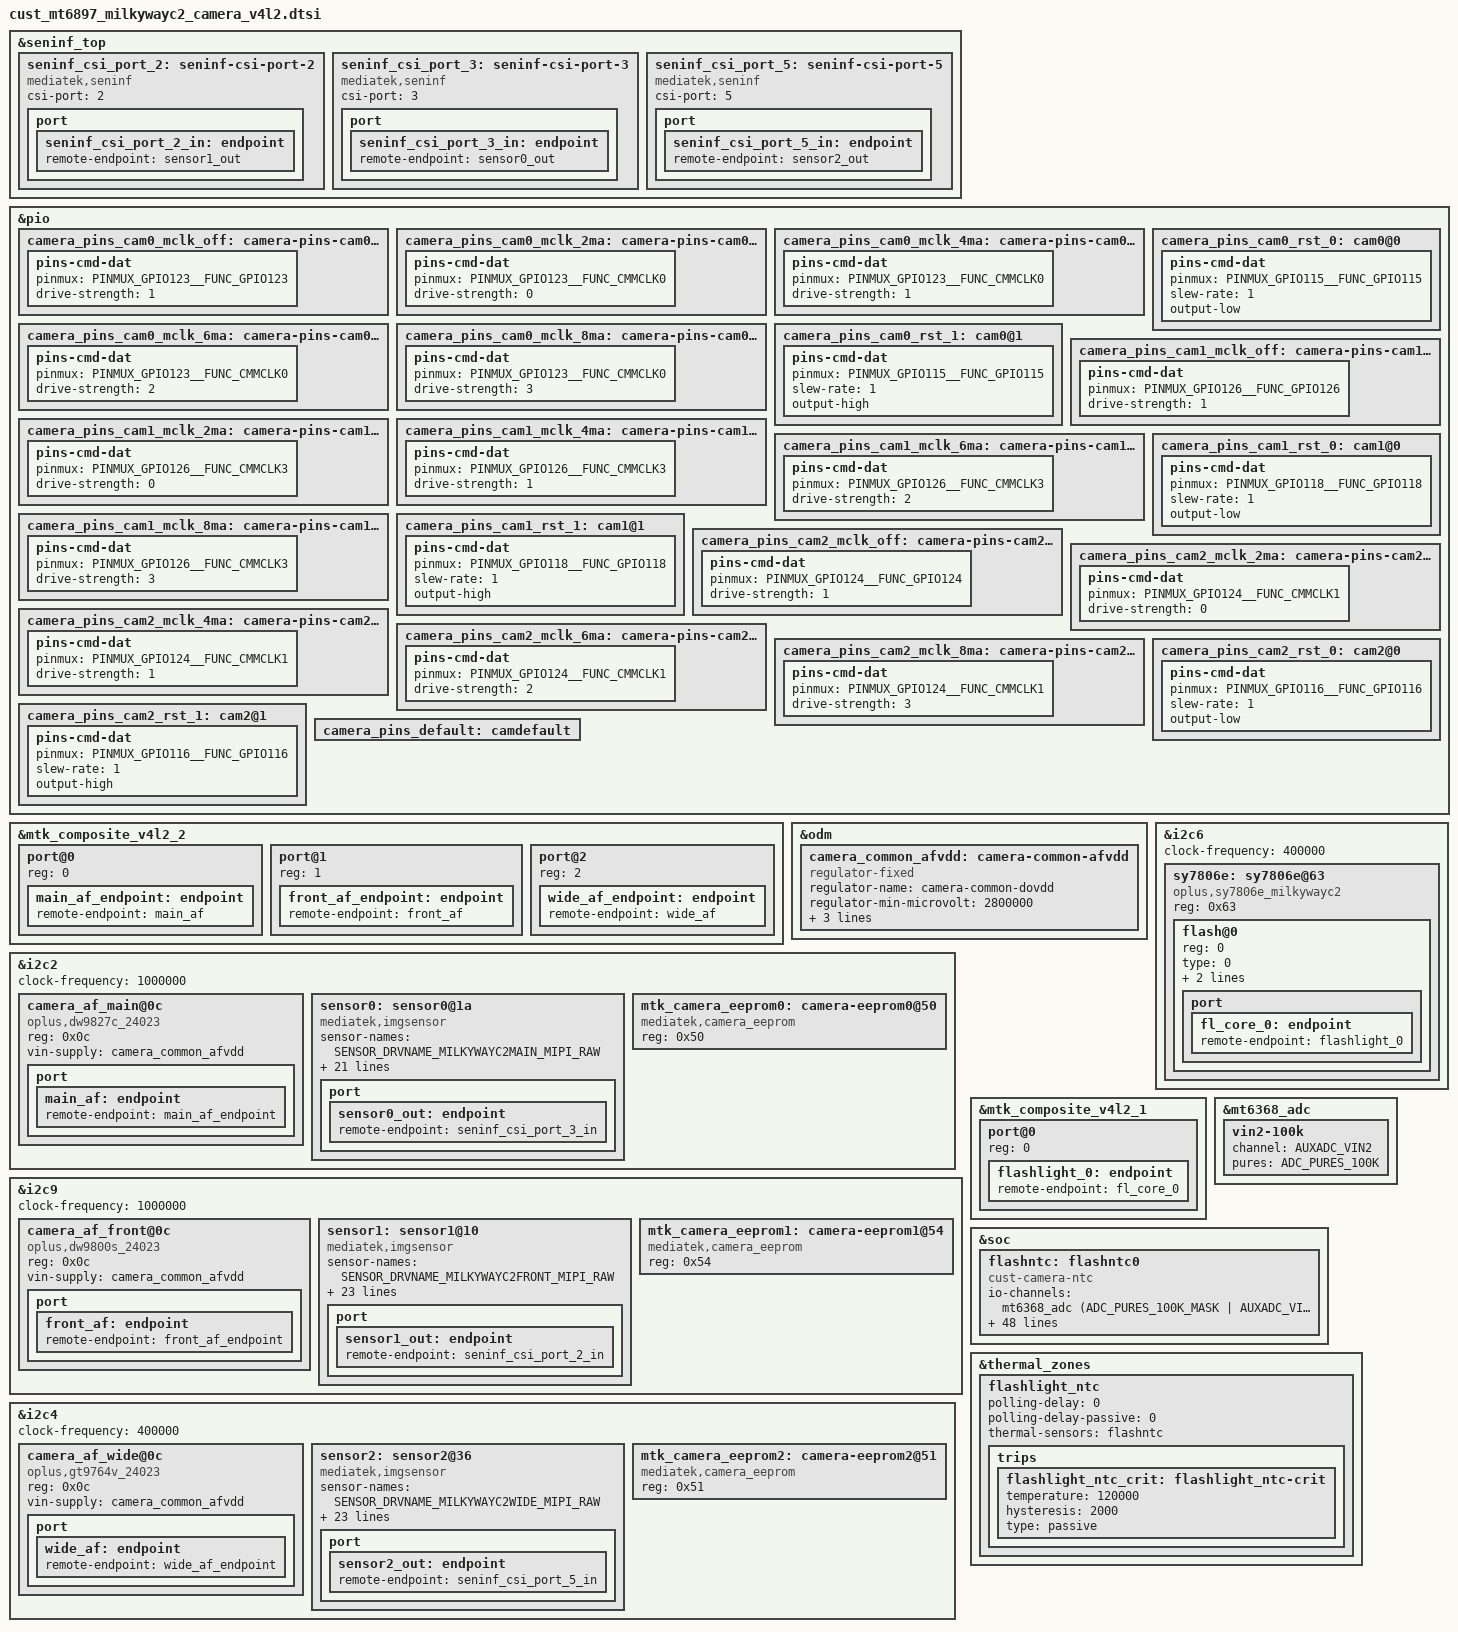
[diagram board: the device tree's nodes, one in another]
// SPDX-License-Identifier: GPL-2.0
/* Copyright (c) 2020 MediaTek Inc. */
#include <dt-bindings/clock/mt6897-clk.h>
#include "mediatek/milkywayc2_regulator_aw37004dnr.dtsi"
#include "../../../../../../vendor/oplus/kernel/camera/imgsensor/inc/oplus_kd_imgsensor.h"

&seninf_top {
		seninf_csi_port_2: seninf-csi-port-2 {
			compatible = "mediatek,seninf";
			csi-port = "2";

			port {
				seninf_csi_port_2_in: endpoint {
					remote-endpoint = <&sensor1_out>;
				};
			};
		};

		seninf_csi_port_3: seninf-csi-port-3 {
			compatible = "mediatek,seninf";
			csi-port = "3";

			port {
				seninf_csi_port_3_in: endpoint {
					remote-endpoint = <&sensor0_out>;
				};
			};
		};

		seninf_csi_port_5: seninf-csi-port-5 {
			compatible = "mediatek,seninf";
			csi-port = "5";

			port {
				seninf_csi_port_5_in: endpoint {
					remote-endpoint = <&sensor2_out>;
				};
			};
		};
};

/* CAMERA GPIO standardization */
&pio {
	camera_pins_cam0_mclk_off: camera-pins-cam0-mclk-off {
		pins-cmd-dat {
			pinmux = <PINMUX_GPIO123__FUNC_GPIO123>;
			drive-strength = <1>;
		};
	};
	camera_pins_cam0_mclk_2ma: camera-pins-cam0-mclk-2ma {
		pins-cmd-dat {
			pinmux = <PINMUX_GPIO123__FUNC_CMMCLK0>;
			drive-strength = <0>;
		};
	};
	camera_pins_cam0_mclk_4ma: camera-pins-cam0-mclk-4ma {
		pins-cmd-dat {
			pinmux = <PINMUX_GPIO123__FUNC_CMMCLK0>;
			drive-strength = <1>;
		};
	};
	camera_pins_cam0_mclk_6ma: camera-pins-cam0-mclk-6ma {
		pins-cmd-dat {
			pinmux = <PINMUX_GPIO123__FUNC_CMMCLK0>;
			drive-strength = <2>;
		};
	};
	camera_pins_cam0_mclk_8ma: camera-pins-cam0-mclk-8ma {
		pins-cmd-dat {
			pinmux = <PINMUX_GPIO123__FUNC_CMMCLK0>;
			drive-strength = <3>;
		};
	};
	camera_pins_cam0_rst_0: cam0@0 {
		pins-cmd-dat {
			pinmux = <PINMUX_GPIO115__FUNC_GPIO115>;
			slew-rate = <1>;
			output-low;
		};
	};
	camera_pins_cam0_rst_1: cam0@1 {
		pins-cmd-dat {
			pinmux = <PINMUX_GPIO115__FUNC_GPIO115>;
			slew-rate = <1>;
			output-high;
		};
	};

	camera_pins_cam1_mclk_off: camera-pins-cam1-mclk-off {
		pins-cmd-dat {
			pinmux = <PINMUX_GPIO126__FUNC_GPIO126>;
			drive-strength = <1>;
		};
	};
	camera_pins_cam1_mclk_2ma: camera-pins-cam1-mclk-2ma {
		pins-cmd-dat {
			pinmux = <PINMUX_GPIO126__FUNC_CMMCLK3>;
			drive-strength = <0>;
		};
	};
	camera_pins_cam1_mclk_4ma: camera-pins-cam1-mclk-4ma {
		pins-cmd-dat {
			pinmux = <PINMUX_GPIO126__FUNC_CMMCLK3>;
			drive-strength = <1>;
		};
	};
	camera_pins_cam1_mclk_6ma: camera-pins-cam1-mclk-6ma {
		pins-cmd-dat {
			pinmux = <PINMUX_GPIO126__FUNC_CMMCLK3>;
			drive-strength = <2>;
		};
	};
	camera_pins_cam1_mclk_8ma: camera-pins-cam1-mclk-8ma {
		pins-cmd-dat {
			pinmux = <PINMUX_GPIO126__FUNC_CMMCLK3>;
			drive-strength = <3>;
		};
	};
	camera_pins_cam1_rst_0: cam1@0 {
		pins-cmd-dat {
			pinmux = <PINMUX_GPIO118__FUNC_GPIO118>;
			slew-rate = <1>;
			output-low;
		};
	};
	camera_pins_cam1_rst_1: cam1@1 {
		pins-cmd-dat {
			pinmux = <PINMUX_GPIO118__FUNC_GPIO118>;
			slew-rate = <1>;
			output-high;
		};
	};

	camera_pins_cam2_mclk_off: camera-pins-cam2-mclk-off {
		pins-cmd-dat {
			pinmux = <PINMUX_GPIO124__FUNC_GPIO124>;
			drive-strength = <1>;
		};
	};
	camera_pins_cam2_mclk_2ma: camera-pins-cam2-mclk-2ma {
		pins-cmd-dat {
			pinmux = <PINMUX_GPIO124__FUNC_CMMCLK1>;
			drive-strength = <0>;
		};
	};
	camera_pins_cam2_mclk_4ma: camera-pins-cam2-mclk-4ma {
		pins-cmd-dat {
			pinmux = <PINMUX_GPIO124__FUNC_CMMCLK1>;
			drive-strength = <1>;
		};
	};
	camera_pins_cam2_mclk_6ma: camera-pins-cam2-mclk-6ma {
		pins-cmd-dat {
			pinmux = <PINMUX_GPIO124__FUNC_CMMCLK1>;
			drive-strength = <2>;
		};
	};
	camera_pins_cam2_mclk_8ma: camera-pins-cam2-mclk-8ma {
		pins-cmd-dat {
			pinmux = <PINMUX_GPIO124__FUNC_CMMCLK1>;
			drive-strength = <3>;
		};
	};
	camera_pins_cam2_rst_0: cam2@0 {
		pins-cmd-dat {
			pinmux = <PINMUX_GPIO116__FUNC_GPIO116>;
			slew-rate = <1>;
			output-low;
		};
	};
	camera_pins_cam2_rst_1: cam2@1 {
		pins-cmd-dat {
			pinmux = <PINMUX_GPIO116__FUNC_GPIO116>;
			slew-rate = <1>;
			output-high;
		};
	};

	camera_pins_default: camdefault {
	};
};
/* CAMERA GPIO end */

&mtk_composite_v4l2_2 {
	#address-cells = <1>;
	#size-cells = <0>;

	port@0 {
		reg = <0>;
		main_af_endpoint: endpoint {
			remote-endpoint = <&main_af>;
		};
	};
	port@1 {
		reg = <1>;
		front_af_endpoint: endpoint {
			remote-endpoint = <&front_af>;
		};
	};

	port@2 {
		reg = <2>;
		wide_af_endpoint: endpoint {
			remote-endpoint = <&wide_af>;
		};
	};
};

&odm {
	camera_common_afvdd: camera-common-afvdd {
		compatible = "regulator-fixed";
		regulator-name = "camera-common-dovdd";
		regulator-min-microvolt = <2800000>;
		regulator-max-microvolt = <2800000>;
		enable-active-high;
		gpio = <&pio 127 0x0>;
	};
};

&i2c2 {
	status = "okay";
	clock-frequency = <1000000>;

	camera_af_main@0c {
		compatible = "oplus,dw9827c_24023";
		reg = <0x0c>;
		vin-supply = <&camera_common_afvdd>;
		port {
			main_af: endpoint {
				remote-endpoint = <&main_af_endpoint>;
			};
		};
	};

	sensor0: sensor0@1a {
		compatible = "mediatek,imgsensor";
		sensor-names = SENSOR_DRVNAME_MILKYWAYC2MAIN_MIPI_RAW;
		sensor-ids = <MILKYWAYC2MAIN_SENSOR_ID>;
		reg = <0x1a>;

		#thermal-sensor-cells = <0>;

		pinctrl-names = "mclk_off",
				"mclk_2mA",
				"mclk_4mA",
				"mclk_6mA",
				"mclk_8mA",
				"rst_low",
				"rst_high";
		pinctrl-0 = <&camera_pins_cam0_mclk_off>;
		pinctrl-1 = <&camera_pins_cam0_mclk_2ma>;
		pinctrl-2 = <&camera_pins_cam0_mclk_4ma>;
		pinctrl-3 = <&camera_pins_cam0_mclk_6ma>;
		pinctrl-4 = <&camera_pins_cam0_mclk_8ma>;
		pinctrl-5 = <&camera_pins_cam0_rst_0>;
		pinctrl-6 = <&camera_pins_cam0_rst_1>;

		avdd-supply = <&aw37004dnr_avdd1>;
		dvdd-supply = <&aw37004dnr_dvdd1>;
		dovdd-supply = <&mt6368_vfp>;
		afvdd-supply = <&camera_common_afvdd>;

		clocks = <&topckgen_clk CLK_TOP_UNIVPLL_192M_D32>,
			<&topckgen_clk CLK_TOP_UNIVPLL_192M_D16>,
			<&topckgen_clk CLK_TOP_F26M_CK_D2>,
			<&topckgen_clk CLK_TOP_UNIVPLL_192M_D10>,
			<&topckgen_clk CLK_TOP_UNIVPLL_192M_D8>,
			<&topckgen_clk CLK_TOP_UNIVPLL_D6_D16>,
			<&topckgen_clk CLK_TOP_UNIVPLL_D6_D8>,
			<&vlp_cksys_clk CLK_VLP_CK_CAMTG_SEL>;  //mclk0
		clock-names = "6", "12", "13", "19.2", "24", "26", "52", "mclk";

		status = "okay";
		port {
			sensor0_out: endpoint {
				remote-endpoint = <&seninf_csi_port_3_in>;
			};
		};
	};

	mtk_camera_eeprom0:camera-eeprom0@50 {
		compatible = "mediatek,camera_eeprom";
		reg = <0x50>;
		status = "okay";
	};
};

&i2c9 {
	status = "okay";
	clock-frequency = <1000000>;

	camera_af_front@0c {
		compatible = "oplus,dw9800s_24023";
		reg = <0x0c>;
		vin-supply = <&camera_common_afvdd>;
		port {
			front_af: endpoint {
				remote-endpoint = <&front_af_endpoint>;
			};
		};
	};

	sensor1: sensor1@10 {
		compatible = "mediatek,imgsensor";
		sensor-names = SENSOR_DRVNAME_MILKYWAYC2FRONT_MIPI_RAW;
		sensor-ids = <MILKYWAYC2FRONT_SENSOR_ID>;
		reg = <0x10>;
		#reindex-to = <0>;
		#cust-aov-csi-clk = <312>;
		#thermal-sensor-cells = <0>;

		pinctrl-names = "mclk_off",
				"mclk_2mA",
				"mclk_4mA",
				"mclk_6mA",
				"mclk_8mA",
				"rst_low",
				"rst_high";

		pinctrl-0 = <&camera_pins_cam1_mclk_off>;
		pinctrl-1 = <&camera_pins_cam1_mclk_2ma>;
		pinctrl-2 = <&camera_pins_cam1_mclk_4ma>;
		pinctrl-3 = <&camera_pins_cam1_mclk_6ma>;
		pinctrl-4 = <&camera_pins_cam1_mclk_8ma>;
		pinctrl-5 = <&camera_pins_cam1_rst_0>;
		pinctrl-6 = <&camera_pins_cam1_rst_1>;

		avdd-supply = <&aw37004dnr_avdd2>;
		dvdd-supply = <&aw37004dnr_dvdd2>;
		dovdd-supply = <&mt6368_vfp>;
		afvdd-supply = <&camera_common_afvdd>;

		clocks = <&topckgen_clk CLK_TOP_UNIVPLL_192M_D32>,
			<&topckgen_clk CLK_TOP_UNIVPLL_192M_D16>,
			<&topckgen_clk CLK_TOP_F26M_CK_D2>,
			<&topckgen_clk CLK_TOP_UNIVPLL_192M_D10>,
			<&topckgen_clk CLK_TOP_UNIVPLL_192M_D8>,
			<&topckgen_clk CLK_TOP_UNIVPLL_D6_D16>,
			<&topckgen_clk CLK_TOP_UNIVPLL_D6_D8>,
			<&topckgen_clk CLK_TOP_CAMTG4_SEL>;   //mclk3
		clock-names = "6", "12", "13", "19.2", "24", "26", "52", "mclk";

		status = "okay";
		port {
			sensor1_out: endpoint {
				remote-endpoint = <&seninf_csi_port_2_in>;
			};
		};
	};

    mtk_camera_eeprom1:camera-eeprom1@54 {
		compatible = "mediatek,camera_eeprom";
		reg = <0x54>;
		status = "okay";
	};
};

&i2c4 {
	status = "okay";
	clock-frequency = <400000>;

	camera_af_wide@0c {
		compatible = "oplus,gt9764v_24023";
		reg = <0x0c>;
		vin-supply = <&camera_common_afvdd>;
		port {
			wide_af: endpoint {
				remote-endpoint = <&wide_af_endpoint>;
			};
		};
	};

   sensor2: sensor2@36 {
		compatible = "mediatek,imgsensor";
		sensor-names = SENSOR_DRVNAME_MILKYWAYC2WIDE_MIPI_RAW;
		sensor-ids = <MILKYWAYC2WIDE_SENSOR_ID>;
		reg = <0x36>;
		#reindex-to = <0>;
		#cust-aov-csi-clk = <312>;
		#thermal-sensor-cells = <0>;

		pinctrl-names = "mclk_off",
				"mclk_2mA",
				"mclk_4mA",
				"mclk_6mA",
				"mclk_8mA",
				"rst_low",
				"rst_high";

		pinctrl-0 = <&camera_pins_cam2_mclk_off>;
		pinctrl-1 = <&camera_pins_cam2_mclk_2ma>;
		pinctrl-2 = <&camera_pins_cam2_mclk_4ma>;
		pinctrl-3 = <&camera_pins_cam2_mclk_6ma>;
		pinctrl-4 = <&camera_pins_cam2_mclk_8ma>;
		pinctrl-5 = <&camera_pins_cam2_rst_0>;
		pinctrl-6 = <&camera_pins_cam2_rst_1>;

		avdd-supply = <&aw37004dnr_avdd1>;
		dvdd-supply = <&mt6368_vrf13_aif>;
		dovdd-supply = <&mt6368_vfp>;
		afvdd-supply = <&camera_common_afvdd>;

		clocks = <&topckgen_clk CLK_TOP_UNIVPLL_192M_D32>,
			<&topckgen_clk CLK_TOP_UNIVPLL_192M_D16>,
			<&topckgen_clk CLK_TOP_F26M_CK_D2>,
			<&topckgen_clk CLK_TOP_UNIVPLL_192M_D10>,
			<&topckgen_clk CLK_TOP_UNIVPLL_192M_D8>,
			<&topckgen_clk CLK_TOP_UNIVPLL_D6_D16>,
			<&topckgen_clk CLK_TOP_UNIVPLL_D6_D8>,
			<&topckgen_clk CLK_TOP_CAMTG2_SEL>;  //mclk1
		clock-names = "6", "12", "13", "19.2", "24", "26", "52", "mclk";

		status = "okay";
		port {
			sensor2_out: endpoint {
				remote-endpoint = <&seninf_csi_port_5_in>;
			};
		};
	};

	mtk_camera_eeprom2:camera-eeprom2@51 {
		compatible = "mediatek,camera_eeprom";
		reg = <0x51>;
		status = "okay";
	};
};

//flashlight
//&pio {
//	sy7806e_pins_default: default {
//	};
//
//	sy7806e_pins_hwen_high: hwen-high {
//		pins_cmd_dat {
//			pinmux = <PINMUX_GPIO153__FUNC_GPIO153>;// nobody use,just test
//			slew-rate = <1>;
//			output-high;
//		};
//	};
//
//	sy7806e_pins_hwen_low: hwen-low {
//		pins_cmd_dat {
//			pinmux = <PINMUX_GPIO153__FUNC_GPIO153>;
//			slew-rate = <1>;
//			output-low;
//		};
//	};
//};

&i2c6 {
	clock-frequency = <400000>;
	#address-cells = <1>;
	#size-cells = <0>;
	sy7806e:sy7806e@63 {
		compatible = "oplus,sy7806e_milkywayc2";
		#address-cells = <1>;
		#size-cells = <0>;
		reg = <0x63>;
		#cooling-cells = <2>;
//		pinctrl-names = "default", "hwen-high", "hwen-low";
//		pinctrl-0 = <&sy7806e_pins_default>;
//		pinctrl-1 = <&sy7806e_pins_hwen_high>;
//		pinctrl-2 = <&sy7806e_pins_hwen_low>;
		status = "okay";
		flash@0{
			reg = <0>;
			type = <0>;
			ct = <0>;
			part = <0>;
			port {
				fl_core_0: endpoint {
					remote-endpoint = <&flashlight_0>;
				};
			};
		};
	};
};

&mtk_composite_v4l2_1 {
	#address-cells = <1>;
	#size-cells = <0>;
	port@0 {
		reg = <0>;
		flashlight_0: endpoint {
			remote-endpoint = <&fl_core_0>;
		};
	};
};


&mt6368_adc {
	vin2-100k {
		channel = <AUXADC_VIN2>;
		pures = <ADC_PURES_100K>;
	};
};

&soc {
	flashntc: flashntc0 {
		compatible = "cust-camera-ntc";
		#thermal-sensor-cells = <0>;
		io-channels = <&mt6368_adc (ADC_PURES_100K_MASK | AUXADC_VIN2)>;
		io-channel-names = "sensor-channel";
		temperature-lookup-table =
			<(-40000) 1799>,
			<(-39000) 1796>,
			<(-38000) 1793>,
			<(-37000) 1790>,
			<(-36000) 1786>,
			<(-35000) 1782>,
			<(-34000) 1778>,
			<(-33000) 1774>,
			<(-32000) 1770>,
			<(-31000) 1765>,
			<(-30000) 1760>,
			<(-29000) 1755>,
			<(-28000) 1749>,
			<(-27000) 1743>,
			<(-26000) 1737>,
			<(-25000) 1731>,
			<(-24000) 1724>,
			<(-23000) 1717>,
			<(-22000) 1709>,
			<(-21000) 1701>,
			<(-20000) 1693>,
			<(-19000) 1684>,
			<(-18000) 1675>,
			<(-17000) 1666>,
			<(-16000) 1656>,
			<(-15000) 1646>,
			<(-14000) 1635>,
			<(-13000) 1624>,
			<(-12000) 1612>,
			<(-11000) 1600>,
			<(-10000) 1588>,
			<(-9000) 1575>,
			<(-8000) 1562>,
			<(-7000) 1548>,
			<(-6000) 1533>,
			<(-5000) 1519>,
			<(-4000) 1503>,
			<(-3000) 1488>,
			<(-2000) 1472>,
			<(-1000) 1455>,
			<0 1438>,
			<1000 1421>,
			<2000 1403>,
			<3000 1385>,
			<4000 1366>,
			<5000 1347>,
			<6000 1328>,
			<7000 1308>,
			<8000 1289>,
			<9000 1268>,
			<10000 1248>,
			<11000 1227>,
			<12000 1206>,
			<13000 1185>,
			<14000 1164>,
			<15000 1142>,
			<16000 1120>,
			<17000 1099>,
			<18000 1077>,
			<19000 1055>,
			<20000 1033>,
			<21000 1011>,
			<22000 990>,
			<23000 968>,
			<24000 946>,
			<25000 925>,
			<26000 903>,
			<27000 882>,
			<28000 861>,
			<29000 840>,
			<30000 819>,
			<31000 799>,
			<32000 778>,
			<33000 758>,
			<34000 739>,
			<35000 719>,
			<36000 700>,
			<37000 681>,
			<38000 663>,
			<39000 645>,
			<40000 627>,
			<41000 609>,
			<42000 592>,
			<43000 576>,
			<44000 559>,
			<45000 543>,
			<46000 528>,
			<47000 512>,
			<48000 498>,
			<49000 483>,
			<50000 469>,
			<51000 455>,
			<52000 442>,
			<53000 429>,
			<54000 416>,
			<55000 404>,
			<56000 392>,
			<57000 380>,
			<58000 368>,
			<59000 357>,
			<60000 347>,
			<61000 336>,
			<62000 326>,
			<63000 317>,
			<64000 307>,
			<65000 298>,
			<66000 289>,
			<67000 280>,
			<68000 272>,
			<69000 264>,
			<70000 256>,
			<71000 249>,
			<72000 241>,
			<73000 234>,
			<74000 227>,
			<75000 221>,
			<76000 214>,
			<77000 208>,
			<78000 202>,
			<79000 196>,
			<80000 191>,
			<81000 185>,
			<82000 180>,
			<83000 175>,
			<84000 170>,
			<85000 165>,
			<86000 161>,
			<87000 156>,
			<88000 152>,
			<89000 148>,
			<90000 144>,
			<91000 140>,
			<92000 136>,
			<93000 133>,
			<94000 129>,
			<95000 126>,
			<96000 122>,
			<97000 119>,
			<98000 116>,
			<99000 113>,
			<100000 110>,
			<101000 108>,
			<102000 105>,
			<103000 102>,
			<104000 100>,
			<105000 97>,
			<106000 95>,
			<107000 93>,
			<108000 91>,
			<109000 89>,
			<110000 87>,
			<111000 85>,
			<112000 83>,
			<113000 81>,
			<114000 79>,
			<115000 77>,
			<116000 76>,
			<117000 74>,
			<118000 72>,
			<119000 71>,
			<120000 69>,
			<121000 68>,
			<122000 67>,
			<123000 65>,
			<124000 64>,
			<125000 63>;
	};
};

&thermal_zones {
	flashlight_ntc: flashlight_ntc {
		polling-delay = <0>; /* milliseconds */
		polling-delay-passive = <0>; /* milliseconds */
		thermal-sensors = <&flashntc>;
		trips {
			flashlight_ntc_crit: flashlight_ntc-crit {
				temperature = <120000>;
				hysteresis = <2000>;
				type = "passive";
			};
		};
	};
};



